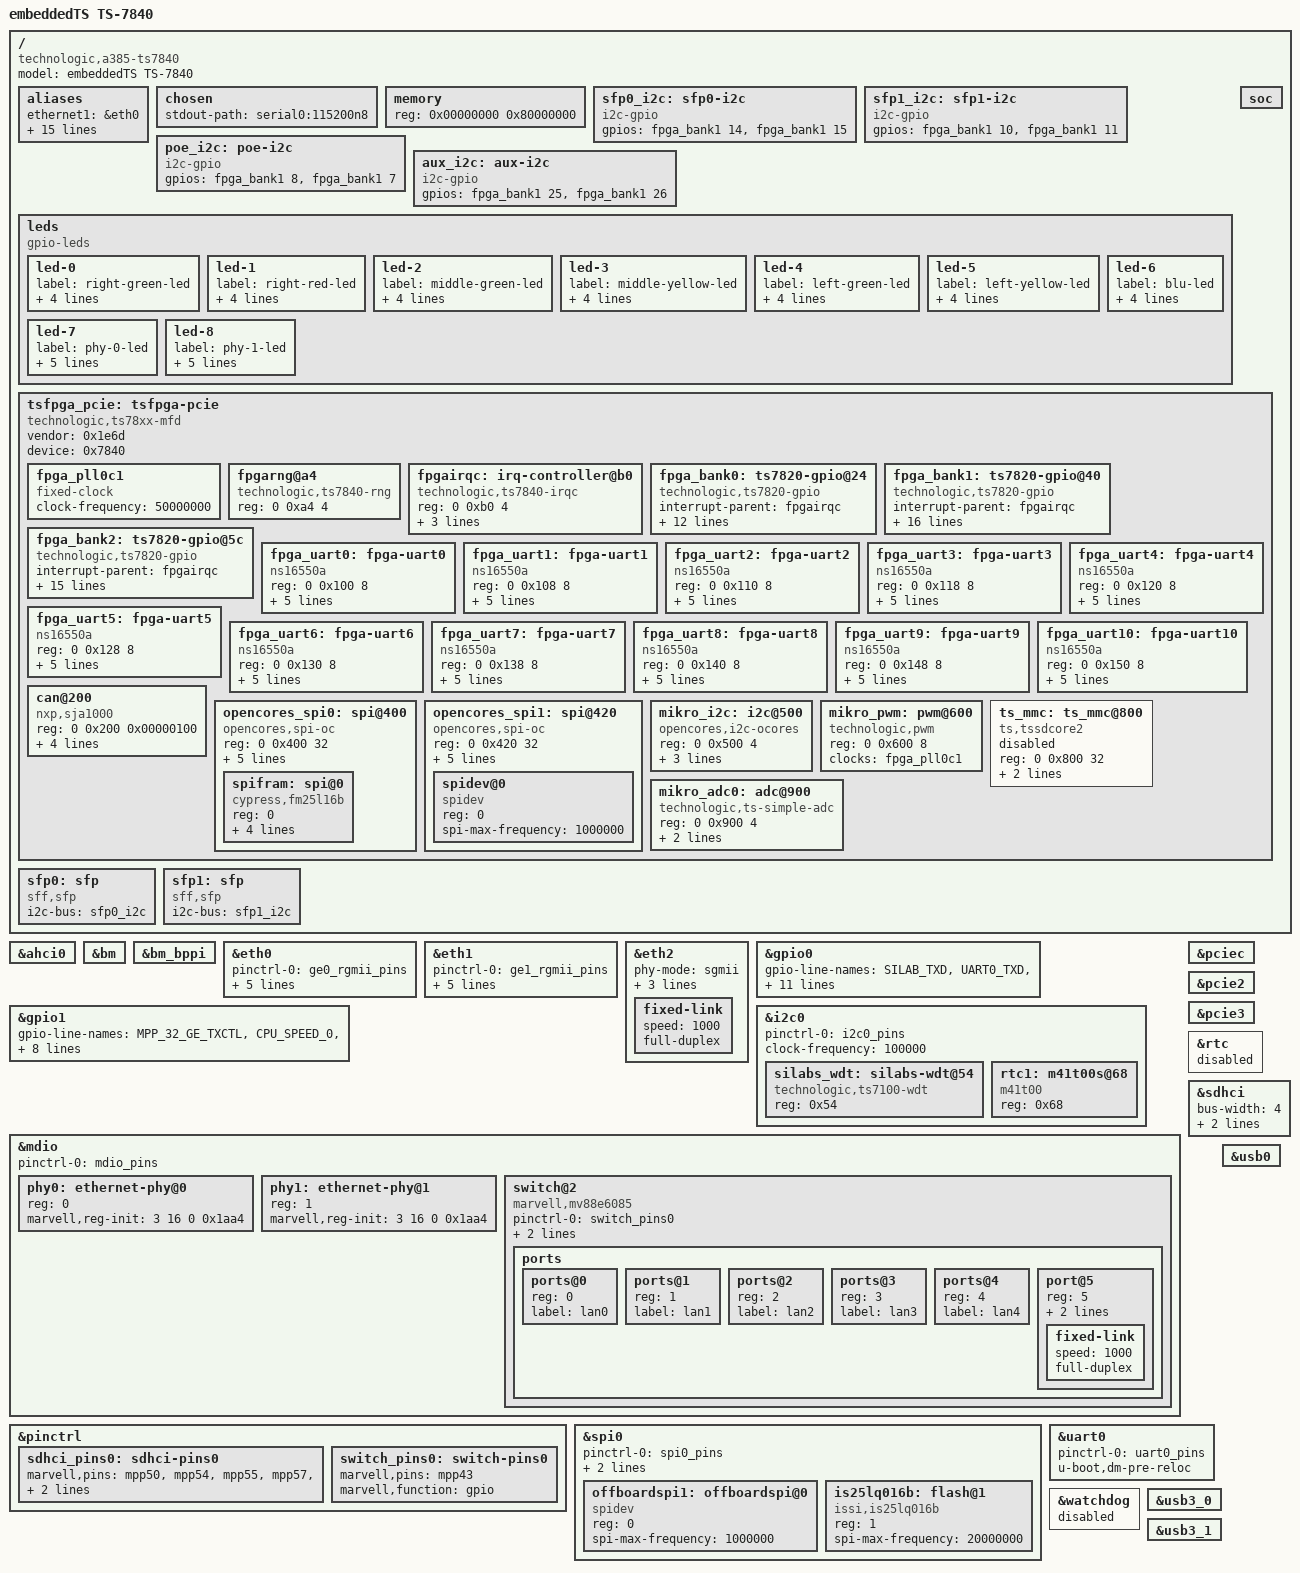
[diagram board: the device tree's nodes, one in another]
/*
 * Device Tree file for embeddedTS TS-7820
 *
 *  Copyright (C) 2017-2022 Technologic Systems, Inc. dba embeddedTS
 *
 * Mark Featherston <mark@embeddedTS.com>
 *
 * This file is dual-licensed: you can use it either under the terms
 * of the GPL or the X11 license, at your option. Note that this dual
 * licensing only applies to this file, and not this project as a
 * whole.
 *
 *  a) This file is licensed under the terms of the GNU General Public
 *     License version 2.  This program is licensed "as is" without
 *     any warranty of any kind, whether express or implied.
 *
 * Or, alternatively,
 *
 *  b) Permission is hereby granted, free of charge, to any person
 *     obtaining a copy of this software and associated documentation
 *     files (the "Software"), to deal in the Software without
 *     restriction, including without limitation the rights to use,
 *     copy, modify, merge, publish, distribute, sublicense, and/or
 *     sell copies of the Software, and to permit persons to whom the
 *     Software is furnished to do so, subject to the following
 *     conditions:
 *
 *     The above copyright notice and this permission notice shall be
 *     included in all copies or substantial portions of the Software.
 *
 *     THE SOFTWARE IS PROVIDED "AS IS", WITHOUT WARRANTY OF ANY KIND,
 *     EXPRESS OR IMPLIED, INCLUDING BUT NOT LIMITED TO THE WARRANTIES
 *     OF MERCHANTABILITY, FITNESS FOR A PARTICULAR PURPOSE AND
 *     NONINFRINGEMENT. IN NO EVENT SHALL THE AUTHORS OR COPYRIGHT
 *     HOLDERS BE LIABLE FOR ANY CLAIM, DAMAGES OR OTHER LIABILITY,
 *     WHETHER IN AN ACTION OF CONTRACT, TORT OR OTHERWISE, ARISING
 *     FROM, OUT OF OR IN CONNECTION WITH THE SOFTWARE OR THE USE OR
 *     OTHER DEALINGS IN THE SOFTWARE.
 */

/dts-v1/;
#include "armada-385.dtsi"

#include <dt-bindings/gpio/gpio.h>
#include <dt-bindings/leds/common.h>
#include <dt-bindings/interrupt-controller/irq.h>

/ {
	model = "embeddedTS TS-7840";
	compatible = "technologic,a385-ts7840", "marvell,armada385", "marvell,armada380";

	aliases {
		ethernet1 = &eth0;
		ethernet2 = &eth1;
		ethernet3 = &eth2;

		gpio2 = &fpga_bank0;
		gpio3 = &fpga_bank1;
		gpio4 = &fpga_bank2;

		spi0 = &spi0;
		spi3 = &opencores_spi0;
		spi4 = &opencores_spi1;

		i2c0 = &i2c0;
		i2c1 = &i2c1;
		i2c2 = &sfp0_i2c;
		i2c3 = &sfp1_i2c;
		i2c3 = &sfp1_i2c;
		i2c4 = &poe_i2c;
		i2c5 = &aux_i2c;
		i2c6 = &mikro_i2c;
	};

	chosen {
		stdout-path = "serial0:115200n8";
	};

	memory {
		device_type = "memory";
		reg = <0x00000000 0x80000000>; /* 2GB */
	};

	sfp0_i2c: sfp0-i2c {
		compatible = "i2c-gpio";
		gpios = <&fpga_bank1 14 (GPIO_ACTIVE_HIGH | GPIO_OPEN_DRAIN)>, /* sda */
			<&fpga_bank1 15 (GPIO_ACTIVE_HIGH | GPIO_OPEN_DRAIN)>; /* scl */
		#address-cells = <1>;
		#size-cells = <0>;
	};

	sfp1_i2c: sfp1-i2c {
		compatible = "i2c-gpio";
		gpios = <&fpga_bank1 10 (GPIO_ACTIVE_HIGH | GPIO_OPEN_DRAIN)>, /* sda */
			<&fpga_bank1 11 (GPIO_ACTIVE_HIGH | GPIO_OPEN_DRAIN)>; /* scl */
		#address-cells = <1>;
		#size-cells = <0>;
	};

	poe_i2c: poe-i2c {
		compatible = "i2c-gpio";
		gpios = <&fpga_bank1 8 (GPIO_ACTIVE_HIGH | GPIO_OPEN_DRAIN)>, /* sda */
			<&fpga_bank1 7 (GPIO_ACTIVE_HIGH | GPIO_OPEN_DRAIN)>; /* scl */
		#address-cells = <1>;
		#size-cells = <0>;
	};

	aux_i2c: aux-i2c {
		compatible = "i2c-gpio";
		gpios = <&fpga_bank1 25 (GPIO_ACTIVE_HIGH | GPIO_OPEN_DRAIN)>, /* sda */
			<&fpga_bank1 26 (GPIO_ACTIVE_HIGH | GPIO_OPEN_DRAIN)>; /* scl */
		#address-cells = <1>;
		#size-cells = <0>;
	};

	leds {
		compatible = "gpio-leds";

		led-0 {
			label = "right-green-led";
			color = <LED_COLOR_ID_GREEN>;
			function = LED_FUNCTION_POWER;
			gpios = <&fpga_bank0 19 GPIO_ACTIVE_LOW>;
			linux,default-trigger = "heartbeat";
		};

		led-1 {
			label = "right-red-led";
			color = <LED_COLOR_ID_RED>;
			function = LED_FUNCTION_STATUS;
			gpios = <&fpga_bank0 20 GPIO_ACTIVE_LOW>;
			default-state = "off";
		};

		led-2 {
			label = "middle-green-led";
			color = <LED_COLOR_ID_GREEN>;
			function = LED_FUNCTION_INDICATOR;
			gpios = <&fpga_bank0 21 GPIO_ACTIVE_LOW>;
			default-state = "off";
		};

		led-3 {
			label = "middle-yellow-led";
			color = <LED_COLOR_ID_YELLOW>;
			function = LED_FUNCTION_INDICATOR;
			gpios = <&fpga_bank0 22 GPIO_ACTIVE_LOW>;
			default-state = "off";
		};

		led-4 {
			label = "left-green-led";
			color = <LED_COLOR_ID_GREEN>;
			function = LED_FUNCTION_INDICATOR;
			gpios = <&fpga_bank0 23 GPIO_ACTIVE_LOW>;
			default-state = "off";
		};

		led-5 {
			label = "left-yellow-led";
			color = <LED_COLOR_ID_YELLOW>;
			function = LED_FUNCTION_INDICATOR;
			gpios = <&fpga_bank0 24 GPIO_ACTIVE_LOW>;
			default-state = "off";
		};

		led-6 {
			label = "blu-led";
			color = <LED_COLOR_ID_BLUE>;
			function = LED_FUNCTION_INDICATOR;
			gpios = <&fpga_bank0 25 GPIO_ACTIVE_HIGH>;
			default-state = "off";
		};

		led-7 {
			label = "phy-0-led";
			color = <LED_COLOR_ID_GREEN>;
			gpios = <&fpga_bank0 26 GPIO_ACTIVE_LOW>;
			function = LED_FUNCTION_INDICATOR;
			linux,default-trigger = "f1072004.mdio-mii:01:1Gbps";
		};

		led-8 {
			label = "phy-1-led";
			color = <LED_COLOR_ID_GREEN>;
			gpios = <&fpga_bank2 20 GPIO_ACTIVE_LOW>;
			function = LED_FUNCTION_INDICATOR;
			linux,default-trigger = "f1072004.mdio-mii:00:1Gbps";
		};
	};

	soc {
		ranges = <MBUS_ID(0xf0, 0x01) 0 0xf1000000 0x100000
			  MBUS_ID(0x01, 0x1d) 0 0xfff00000 0x100000
			  MBUS_ID(0x09, 0x19) 0 0xf1100000 0x10000
			  MBUS_ID(0x09, 0x15) 0 0xf1110000 0x10000
			  MBUS_ID(0x0c, 0x04) 0 0xf1200000 0x100000>;
	};

	tsfpga_pcie: tsfpga-pcie {
		compatible = "technologic,ts78xx-mfd";
		#address-cells = <2>;
		#size-cells = <1>;

		vendor = <0x1e6d>;
		device = <0x7840>;

		/* <ranges> is set in the driver at runtime */

		fpga_pll0c1: fpga_pll0c1 {
			compatible = "fixed-clock";
			#clock-cells = <0>;
			clock-frequency = <50000000>;
		};

		fpgarng@a4 {
			compatible = "technologic,ts7840-rng";
			reg = <0 0xa4 4>;
		};

		fpgairqc: irq-controller@b0 {
			compatible = "technologic,ts7840-irqc";
			reg = <0 0xb0 4>;
			interrupt-controller;
			#interrupt-cells = <2>;
			interrupt-parent = <&gpio1>;
			interrupts = <3 IRQ_TYPE_LEVEL_HIGH>;
		};

		fpga_bank0: ts7820-gpio@24 {
			compatible = "technologic,ts7820-gpio";

			interrupt-parent = <&fpgairqc>;
			interrupts = <16 IRQ_TYPE_LEVEL_HIGH>;

			interrupt-controller;
			#interrupt-cells = <2>;

			gpio-controller;
			#gpio-cells = <2>;
			reg = <0 0x24 0x1c>;

			gpio-line-names =
				"",
				"",
				"",
				"",
				"",
				"",
				"",
				"",
				"",
				"",
				"",
				"",
				"",
				"",
				"",
				"",
				"power_fail_3v_pad",
				"detect_9478_pad",
				"",
				"magjack_1_led_padn",
				"blu_led_padn",
				"right_grn_led_padn",
				"right_red_led_padn",
				"middle_grn_led_padn",
				"middle_yel_led_padn",
				"left_grn_led_padn",
				"left_yel_led_padn",
				"bt_en_pad",
				"wifi_en_pad",
				"prog_silab_clk_padn",
				"prog_silab_data_pad",
				"cpu_push_sw_padn";
		};

		fpga_bank1: ts7820-gpio@40 {
			compatible = "technologic,ts7820-gpio";

			interrupt-parent = <&fpgairqc>;
			interrupts = <17 IRQ_TYPE_LEVEL_HIGH>;

			interrupt-controller;
			#interrupt-cells = <2>;

			gpio-controller;
			#gpio-cells = <2>;
			reg = <0 0x40 0x1c>;

			gpio-line-names =
				"DIG_IO_1",
				"DIG_IO_2",
				"DIG_IO_3",
				"en_hs_sw_pad",
				"mikro_pwm_pad",
				"dio_fault_3v_padn",
				"en_poe_padn",
				"i2c_poe_clk_pad",
				"i2c_poe_dat",
				"spi_0_fpga_cs3_pad",
				"cage1_sda_pad",
				"cage1_scl_pad",
				"",
				"",
				"cage2_sda_pad",
				"cage2_scl_pad",
				"en_nimbel_4v_pad",
				"en_nimbel_3v3_pad",
				"en_emmc_3v3_pad",
				"en_modem_5v_pad",
				"en_usb_5v_pad",
				"disable_nim_usb_pad",
				"mini_pcie_reset_padn",
				"ssd_present_padn",
				"en_xbee_usb_padn",
				"aux_i2c_dat_pad",
				"aux_i2c_clk_pad",
				"",
				"",
				"",
				"",
				"";
		};

		fpga_bank2: ts7820-gpio@5c {
			compatible = "technologic,ts7820-gpio";

			interrupt-parent = <&fpgairqc>;
			interrupts = <18 IRQ_TYPE_LEVEL_HIGH>;

			interrupt-controller;
			#interrupt-cells = <2>;

			gpio-controller;
			#gpio-cells = <2>;
			reg = <0 0x5c 0x1c>;

			gpio-line-names =
				"ird_network_rdy_pad",
				"ird_modem_on_pad",
				"eth_100_act_padn",
				"eth_100_speed_padn",
				"ssd_act_padn",
				"mini_sr_latch_pad",
				"",
				"",
				"",
				"",
				"mikro_int_pad",
				"mikro_reset_padn",
				"mikro_an_3v_pad",
				"mikro_i2c_clk_pad",
				"mikro_i2c_dat_pad",
				"alt_mikro_pwm_pad",
				"mikro_an_pwm_pad",
				"comp_pad",
				"mikro_180_pad",
				"en_mini_5v_pad",
				"magjack_0_led_padn",
				"hd10_2_pad",
				"hd10_4_pad",
				"hd10_5_pad",
				"hd10_6_pad",
				"hd10_8_pad",
				"jp1_padn",
				"jp2_padn",
				"",
				"",
				"",
				"";
		};

		/* COM1 RS-232 */
		fpga_uart0: fpga-uart0 {
			compatible = "ns16550a";
			reg = <0 0x100 8>;
			interrupt-parent = <&fpgairqc>;
			interrupts = <0 IRQ_TYPE_LEVEL_HIGH>;
			clock-frequency = <1843200>;
			reg-io-width = <1>;
			fifo-size = <64>;
		};

		/* COM2 RS-232 */
		fpga_uart1: fpga-uart1 {
			compatible = "ns16550a";
			reg = <0 0x108 8>;
			interrupt-parent = <&fpgairqc>;
			interrupts = <1 IRQ_TYPE_LEVEL_HIGH>;
			clock-frequency = <1843200>;
			reg-io-width = <1>;
			fifo-size = <64>;
		};

		/* GPS */
		fpga_uart2: fpga-uart2 {
			compatible = "ns16550a";
			reg = <0 0x110 8>;
			interrupt-parent = <&fpgairqc>;
			interrupts = <2 IRQ_TYPE_LEVEL_HIGH>;
			clock-frequency = <1843200>;
			reg-io-width = <1>;
			fifo-size = <64>;
		};

		/* Nimbelink */
		fpga_uart3: fpga-uart3 {
			compatible = "ns16550a";
			reg = <0 0x118 8>;
			interrupt-parent = <&fpgairqc>;
			interrupts = <3 IRQ_TYPE_LEVEL_HIGH>;
			clock-frequency = <1843200>;
			reg-io-width = <1>;
			fifo-size = <64>;
		};

		/* Iridium Modem */
		fpga_uart4: fpga-uart4 {
			compatible = "ns16550a";
			reg = <0 0x120 8>;
			interrupt-parent = <&fpgairqc>;
			interrupts = <4 IRQ_TYPE_LEVEL_HIGH>;
			clock-frequency = <1843200>;
			reg-io-width = <1>;
			fifo-size = <64>;
		};

		/* DSL Modem */
		fpga_uart5: fpga-uart5 {
			compatible = "ns16550a";
			reg = <0 0x128 8>;
			interrupt-parent = <&fpgairqc>;
			interrupts = <5 IRQ_TYPE_LEVEL_HIGH>;
			clock-frequency = <1843200>;
			reg-io-width = <1>;
			fifo-size = <64>;
		};

		/* Mikrobus UART */
		fpga_uart6: fpga-uart6 {
			compatible = "ns16550a";
			reg = <0 0x130 8>;
			interrupt-parent = <&fpgairqc>;
			interrupts = <6 IRQ_TYPE_LEVEL_HIGH>;
			clock-frequency = <1843200>;
			reg-io-width = <1>;
			fifo-size = <64>;
		};

		/* RS-485 port */
		fpga_uart7: fpga-uart7 {
			compatible = "ns16550a";
			reg = <0 0x138 8>;
			interrupt-parent = <&fpgairqc>;
			interrupts = <7 IRQ_TYPE_LEVEL_HIGH>;
			clock-frequency = <1843200>;
			reg-io-width = <1>;
			fifo-size = <64>;
		};

		/* XBEE */
		fpga_uart8: fpga-uart8 {
			compatible = "ns16550a";
			reg = <0 0x140 8>;
			interrupt-parent = <&fpgairqc>;
			interrupts = <8 IRQ_TYPE_LEVEL_HIGH>;
			clock-frequency = <1843200>;
			reg-io-width = <1>;
			fifo-size = <64>;
		};

		/* Spare */
		fpga_uart9: fpga-uart9 {
			compatible = "ns16550a";
			reg = <0 0x148 8>;
			interrupt-parent = <&fpgairqc>;
			interrupts = <19 IRQ_TYPE_LEVEL_HIGH>;
			clock-frequency = <1843200>;
			reg-io-width = <1>;
			fifo-size = <64>;
		};

		/* Spare */
		fpga_uart10: fpga-uart10 {
			compatible = "ns16550a";
			reg = <0 0x150 8>;
			interrupt-parent = <&fpgairqc>;
			interrupts = <20 IRQ_TYPE_LEVEL_HIGH>;
			clock-frequency = <1843200>;
			reg-io-width = <1>;
			fifo-size = <64>;
		};

		can@200 {
			compatible = "nxp,sja1000";
			reg = <0 0x200 0x00000100>;
			interrupt-parent = <&fpgairqc>;
			interrupts = <10 IRQ_TYPE_LEVEL_HIGH>;
			reg-io-width = <1>;
			nxp,external-clock-frequency = <16000000>;
		};

		opencores_spi0: spi@400 {
			compatible = "opencores,spi-oc";
			reg = <0 0x400 32>;
			interrupt-parent = <&fpgairqc>;
			interrupts = <11 IRQ_TYPE_LEVEL_HIGH>;
			clocks = <&fpga_pll0c1>;
			clock-names ="spi-oc-clk";
			opencores-spi,idx = <0>;
			opencores-spi,num-chipselects = <1>;

			#address-cells = <1>;
			#size-cells = <0>;

			spifram: spi@0 {
				compatible = "cypress,fm25l16b", "atmel,at25";
				reg = <0>;
				spi-max-frequency = <19800000>;
				size = <0x800>;
				address-width = <16>;
				pagesize = <64>;
			};
		};

		opencores_spi1: spi@420 {
			compatible = "opencores,spi-oc";
			reg = <0 0x420 32>;
			interrupt-parent = <&fpgairqc>;
			interrupts = <12 IRQ_TYPE_LEVEL_HIGH>;
			clocks = <&fpga_pll0c1>;
			clock-names ="spi-oc-clk";
			opencores-spi,idx = <0>;
			opencores-spi,num-chipselects = <1>;

			#address-cells = <1>;
			#size-cells = <0>;

			spidev@0 {
				compatible = "spidev";
				reg = <0>;
				spi-max-frequency = <1000000>;
			};
		};

		mikro_i2c: i2c@500 {
			compatible = "opencores,i2c-ocores";
			reg = <0 0x500 4>;
			interrupt-parent = <&fpgairqc>;
			interrupts = <13 IRQ_TYPE_LEVEL_HIGH>;
			clocks = <&fpga_pll0c1>;
			clock-names = "i2c-oc-clk";
		};

		mikro_pwm: pwm@600 {
			compatible = "technologic,pwm";
			reg = <0 0x600 8>;
			clocks = <&fpga_pll0c1>;
			clock-names = "pwm-input-clk";
		};

		ts_mmc: ts_mmc@800 {
			compatible = "ts,tssdcore2";
			reg = <0 0x800 32>;
			//interrupt-parent = <&fpgairqc>;
			//interrupts = <14 IRQ_TYPE_LEVEL_HIGH>;
			busy-gpios = <&fpga_bank0 15 0>;
			debug-gpios = <&fpga_bank1 12 0>;
			status = "disabled";
		};

		mikro_adc0: adc@900 {
			compatible = "technologic,ts-simple-adc";
			reg = <0 0x900 4>;
			interrupt-parent = <&fpgairqc>;
			interrupts = <21 IRQ_TYPE_LEVEL_HIGH>;
		};
	};

	sfp0: sfp {
		compatible = "sff,sfp";
		i2c-bus = <&sfp0_i2c>;
	};

	sfp1: sfp {
		compatible = "sff,sfp";
		i2c-bus = <&sfp1_i2c>;
	};
};

&ahci0 {
	status = "okay";
};

&bm {
	status = "okay";
};

&bm_bppi {
	status = "okay";
};

/* magjack/sfp port 0 */
&eth0 {
	pinctrl-names = "default";
	pinctrl-0 = <&ge0_rgmii_pins>;
	status = "okay";
	phy = <&phy0>;
	phy-mode = "rgmii-id";
	buffer-manager = <&bm>;
	/*sfp = <&sfp0>;*/
	bm,pool-long = <0>;
	bm,pool-short = <1>;
};

/* magjack/sfgp port 1 */
&eth1 {
	pinctrl-names = "default";
	pinctrl-0 = <&ge1_rgmii_pins>;
	status = "okay";
	phy = <&phy1>;
	phy-mode = "rgmii-id";
	/*sfp = <&sfp1>;*/
	bm,pool-long = <2>;
	bm,pool-short = <1>;
	buffer-manager = <&bm>;
};

/* sgmii port to eth switch */
&eth2 {
	status = "okay";
	phy-mode = "sgmii";
	bm,pool-long = <3>;
	bm,pool-short = <1>;
	buffer-manager = <&bm>;

	fixed-link {
		speed = <1000>;
		full-duplex;
	};
};

&gpio0 {
	gpio-line-names =
		"SILAB_TXD",
		"UART0_TXD",
		"I2C_0_CLK",
		"I2C_0_DAT",
		"MPP4_GE_MDC",
		"MPP5_GE_MDIO",
		"MPP6_GE_TXCLK",
		"MPP7_GE_TXD0",
		"MPP8_GE_TXD1",
		"MPP9_GE_TXD2",
		"MPP10_GE_TXD3",
		"MPP11_GE_TXCTL",
		"MPP12_GE_RXD0",
		"MPP13_GE_RXD1",
		"MPP14_GE_RXD2",
		"MPP15_GE_RXD3",
		"MPP16_GE_RXCTL",
		"MPP17_GE_RXCLK",
		"WIFI_IRQ_N",
		"FPGA_RESET",
		"",
		"MPP_21_GE_RXD0",
		"SPI_0_MOSI",
		"SPI_0_CLK",
		"SPI_0_MISO",
		"SPI_0_BOOT_CS0#",
		"",
		"MPP_27_GE_TXCLK",
		"MPP_28_GE_TXD0",
		"MPP_29_GE_TXD1",
		"MPP_30_GE_TXD2",
		"MPP_31_GE_TXD3";
};

&gpio1 {
	gpio-line-names =
		"MPP_32_GE_TXCTL",
		"CPU_SPEED_0",
		"CPU_SPEED_3",
		"CPU_SPEED_4",
		"CPU_TYPE_0",
		"MPP_37_GE_RXCLK",
		"MPP_38_GE_RXD1",
		"MPP_39_GE_RXD2",
		"MPP_40_GE_RXD3",
		"MPP_41_GE_RXCTL",
		"GPS_PPS",
		"ETH_SW_INT#",
		"CPU_TYPE_1",
		"",
		"",
		"",
		"",
		"FPGA_FLASH_SELECT",
		"EMMC_CMD",
		"SPREAD_SPECTRUM#",
		"",
		"DETECT_9478",
		"EMMC_D3",
		"EMMC_D0",
		"",
		"EMMC_CLK",
		"EMMC_D1",
		"EMMC_D2",
		"",
		"",
		"",
		"";
};

&i2c0 {
	pinctrl-names = "default";
	pinctrl-0 = <&i2c0_pins>;
	clock-frequency = <100000>;
	status = "okay";

	silabs_wdt: silabs-wdt@54 {
		compatible = "technologic,ts7100-wdt";
		reg = <0x54>;
	};

	rtc1: m41t00s@68 {
		compatible = "m41t00";
		reg = <0x68>;
	};
};

&mdio {
	pinctrl-names = "default";
	pinctrl-0 = <&mdio_pins>;

	phy0: ethernet-phy@0 {
		reg = <0>;
		/* Configure LED[0] to blink for activity */
		marvell,reg-init = <3 16 0 0x1aa4>;
	};

	phy1: ethernet-phy@1 {
		reg = <1>;
		/* Configure LED[0] to blink for activity */
		marvell,reg-init = <3 16 0 0x1aa4>;
	};

	switch@2 {
		compatible = "marvell,mv88e6085";

		pinctrl-names = "default";
		pinctrl-0 = <&switch_pins0>;

		#address-cells = <1>;
		#size-cells = <0>;
		dsa,member = <0 0>;
		reg = <2>;

		ports {
			#address-cells = <1>;
			#size-cells = <0>;

			ports@0 {
				reg = <0>;
				label = "lan0";
			};

			ports@1 {
				reg = <1>;
				label = "lan1";
			};

			ports@2 {
				reg = <2>;
				label = "lan2";
			};

			ports@3 {
				reg = <3>;
				label = "lan3";
			};

			ports@4 {
				reg = <4>;
				label = "lan4";
			};

			port@5 {
				reg = <5>;
				label = "cpu";
				ethernet = <&eth2>;
				fixed-link {
					speed = <1000>;
					full-duplex;
				};
			};
		};
	};
};

&pciec {
	status = "okay";
};

/* Mini PCIe */
&pcie2 {
	status = "okay";
};

/* FPGA */
&pcie3 {
	status = "okay";
};

&pinctrl {
	sdhci_pins0: sdhci-pins0 {
		marvell,pins = "mpp50", "mpp54", "mpp55",
			       "mpp57", "mpp58", "mpp59";
		marvell,function = "sd0";
	};

	switch_pins0: switch-pins0 {
		marvell,pins = "mpp43";
		marvell,function = "gpio";
	};
};

/* We do not use the CPU's built in RTC */
&rtc {
	status = "disabled";
};

&sdhci {
	bus-width = <4>;
	no-1-8-v;
	pinctrl-0 = <&sdhci_pins0>;
	pinctrl-names = "default";
	status = "okay";
};

&spi0 {
	pinctrl-names = "default";
	pinctrl-0 = <&spi0_pins>;
	status = "okay";
	num-cs = <3>;
	cs-gpios = <0>, <&fpga_bank1 9 0>;

	/* CN99 flash */
	offboardspi1: offboardspi@0 {
		compatible = "spidev";
		reg = <0>;
		spi-max-frequency = <1000000>;
	};

	/* Onboard FPGA Flash */
	is25lq016b: flash@1 {
		compatible = "issi,is25lq016b", "jedec,spi-nor";
		reg = <1>;
		spi-max-frequency = <20000000>;
	};
};

&uart0 {
	pinctrl-0 = <&uart0_pins>;
	pinctrl-names = "default";
	status = "okay";
	u-boot,dm-pre-reloc;
};

/* We use an external watchdog */
&watchdog {
	status = "disabled";
};

&usb0 {
	status = "okay";
};

&usb3_0 {
	status = "okay";
};

&usb3_1 {
	status = "okay";
};
